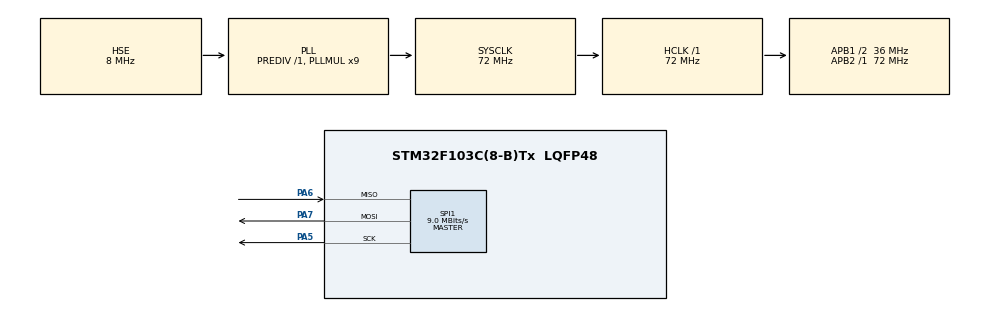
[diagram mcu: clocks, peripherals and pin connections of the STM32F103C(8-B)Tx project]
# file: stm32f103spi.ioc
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Dma.Request0=SPI1_RX
Dma.Request1=SPI1_TX
Dma.SPI1_RX.0.Direction=DMA_PERIPH_TO_MEMORY
Dma.SPI1_RX.0.Instance=DMA1_Channel2
Dma.SPI1_RX.0.MemDataAlignment=DMA_MDATAALIGN_BYTE
Dma.SPI1_RX.0.MemInc=DMA_MINC_ENABLE
Dma.SPI1_RX.0.Mode=DMA_NORMAL
Dma.SPI1_RX.0.PeriphDataAlignment=DMA_PDATAALIGN_BYTE
Dma.SPI1_RX.0.PeriphInc=DMA_PINC_DISABLE
Dma.SPI1_RX.0.Priority=DMA_PRIORITY_LOW
Dma.SPI1_TX.1.Direction=DMA_MEMORY_TO_PERIPH
Dma.SPI1_TX.1.Instance=DMA1_Channel3
Dma.SPI1_TX.1.MemDataAlignment=DMA_MDATAALIGN_BYTE
Dma.SPI1_TX.1.MemInc=DMA_MINC_ENABLE
Dma.SPI1_TX.1.Mode=DMA_NORMAL
Dma.SPI1_TX.1.PeriphDataAlignment=DMA_PDATAALIGN_BYTE
Dma.SPI1_TX.1.PeriphInc=DMA_PINC_DISABLE
Dma.SPI1_TX.1.Priority=DMA_PRIORITY_LOW
Mcu.Family=STM32F1
Mcu.Name=STM32F103C(8-B)Tx
Mcu.Package=LQFP48
NVIC.DMA1_Channel2_IRQn=true\:0\:0\:false\:false\:true\:false\:true
NVIC.DMA1_Channel3_IRQn=true\:0\:0\:false\:false\:true\:false\:true
NVIC.PriorityGroup=NVIC_PRIORITYGROUP_4
NVIC.SPI1_IRQn=true\:0\:0\:false\:false\:true\:true\:true
PA5.Mode=Full_Duplex_Master
PA5.Signal=SPI1_SCK
PA6.Mode=Full_Duplex_Master
PA6.Signal=SPI1_MISO
PA7.Mode=Full_Duplex_Master
PA7.Signal=SPI1_MOSI
PD0-OSC_IN.Mode=HSE-External-Oscillator
PD0-OSC_IN.Signal=RCC_OSC_IN
PD1-OSC_OUT.Mode=HSE-External-Oscillator
PD1-OSC_OUT.Signal=RCC_OSC_OUT
ProjectManager.HeapSize=0x200
ProjectManager.StackSize=0x400
ProjectManager.TargetToolchain=MDK-ARM V5
RCC.AHBFreq_Value=72000000
RCC.APB1CLKDivider=RCC_HCLK_DIV2
RCC.APB1Freq_Value=36000000
RCC.APB1TimFreq_Value=72000000
RCC.APB2Freq_Value=72000000
RCC.APB2TimFreq_Value=72000000
RCC.HCLKFreq_Value=72000000
RCC.PLLMUL=RCC_PLL_MUL9
RCC.PLLSourceVirtual=RCC_PLLSOURCE_HSE
RCC.SYSCLKFreq_VALUE=72000000
RCC.SYSCLKSource=RCC_SYSCLKSOURCE_PLLCLK
RCC.USBFreq_Value=72000000
SPI1.BaudRatePrescaler=SPI_BAUDRATEPRESCALER_8
SPI1.CalculateBaudRate=9.0 MBits/s
SPI1.Direction=SPI_DIRECTION_2LINES
SPI1.Mode=SPI_MODE_MASTER
SPI1.VirtualType=VM_MASTER
VP_SYS_VS_ND.Mode=No_Debug
board=custom

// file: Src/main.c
/* USER CODE BEGIN Header */
/**
  ******************************************************************************
  * @file           : main.c
  * @brief          : Main program body
  ******************************************************************************
  * @attention
  *
  * <h2><center>&copy; Copyright (c) 2021 STMicroelectronics.
  * All rights reserved.</center></h2>
  *
  * This software component is licensed by ST under BSD 3-Clause license,
  * the "License"; You may not use this file except in compliance with the
  * License. You may obtain a copy of the License at:
  *                        opensource.org/licenses/BSD-3-Clause
  *
  ******************************************************************************
  */
/* USER CODE END Header */

#include "main.h"

SPI_HandleTypeDef hspi1;
DMA_HandleTypeDef hdma_spi1_rx;
DMA_HandleTypeDef hdma_spi1_tx;

void SystemClock_Config(void);
static void MX_GPIO_Init(void);
static void MX_DMA_Init(void);
static void MX_SPI1_Init(void);

int main(void)
{

  /* MCU Configuration--------------------------------------------------------*/

  /* Reset of all peripherals, Initializes the Flash interface and the Systick. */
  HAL_Init();

  /* Configure the system clock */
  SystemClock_Config();

  /* Initialize all configured peripherals */
  MX_GPIO_Init();
  MX_DMA_Init();
  MX_SPI1_Init();

  /* Infinite loop */
  /* USER CODE BEGIN WHILE */
  while (1)
  {
		uint8_t pData[4] = {0x00, 0x00, 0x00,0x00};
		static uint8_t cmd[4] = {0x00,0x01,0x02,0x03};
		//HAL_SPI_TransmitReceive(&hspi1, cmd, pData, 4, 10000);
		HAL_SPI_TransmitReceive_DMA(&hspi1, cmd, pData, 4);
		cmd[3] += 1;
		HAL_Delay(5);
//		if (HAL_SPI_Receive(&hspi1, pData,4,280843555) == HAL_OK){
//				if(pData[0] == 0x01 && pData[3] == 0x03){
//						cmd[3] += 1;
//
//				}
//
//		}
    /* USER CODE END WHILE */

  }
}

void SystemClock_Config(void)
{
  RCC_OscInitTypeDef RCC_OscInitStruct = {0};
  RCC_ClkInitTypeDef RCC_ClkInitStruct = {0};

  /** Initializes the CPU, AHB and APB busses clocks
  */
  RCC_OscInitStruct.OscillatorType = RCC_OSCILLATORTYPE_HSE;
  RCC_OscInitStruct.HSEState = RCC_HSE_ON;
  RCC_OscInitStruct.HSEPredivValue = RCC_HSE_PREDIV_DIV1;
  RCC_OscInitStruct.HSIState = RCC_HSI_ON;
  RCC_OscInitStruct.PLL.PLLState = RCC_PLL_ON;
  RCC_OscInitStruct.PLL.PLLSource = RCC_PLLSOURCE_HSE;
  RCC_OscInitStruct.PLL.PLLMUL = RCC_PLL_MUL9;
  if (HAL_RCC_OscConfig(&RCC_OscInitStruct) != HAL_OK)
  {
    Error_Handler();
  }
  /** Initializes the CPU, AHB and APB busses clocks
  */
  RCC_ClkInitStruct.ClockType = RCC_CLOCKTYPE_HCLK|RCC_CLOCKTYPE_SYSCLK
                              |RCC_CLOCKTYPE_PCLK1|RCC_CLOCKTYPE_PCLK2;
  RCC_ClkInitStruct.SYSCLKSource = RCC_SYSCLKSOURCE_PLLCLK;
  RCC_ClkInitStruct.AHBCLKDivider = RCC_SYSCLK_DIV1;
  RCC_ClkInitStruct.APB1CLKDivider = RCC_HCLK_DIV2;
  RCC_ClkInitStruct.APB2CLKDivider = RCC_HCLK_DIV1;

  if (HAL_RCC_ClockConfig(&RCC_ClkInitStruct, FLASH_LATENCY_2) != HAL_OK)
  {
    Error_Handler();
  }
}

static void MX_SPI1_Init(void)
{

  /* SPI1 parameter configuration*/
  hspi1.Instance = SPI1;
  hspi1.Init.Mode = SPI_MODE_MASTER;
  hspi1.Init.Direction = SPI_DIRECTION_2LINES;
  hspi1.Init.DataSize = SPI_DATASIZE_8BIT;
  hspi1.Init.CLKPolarity = SPI_POLARITY_LOW;
  hspi1.Init.CLKPhase = SPI_PHASE_1EDGE;
  hspi1.Init.NSS = SPI_NSS_SOFT;
  hspi1.Init.BaudRatePrescaler = SPI_BAUDRATEPRESCALER_8;
  hspi1.Init.FirstBit = SPI_FIRSTBIT_MSB;
  hspi1.Init.TIMode = SPI_TIMODE_DISABLE;
  hspi1.Init.CRCCalculation = SPI_CRCCALCULATION_DISABLE;
  hspi1.Init.CRCPolynomial = 10;
  if (HAL_SPI_Init(&hspi1) != HAL_OK)
  {
    Error_Handler();
  }

}

static void MX_DMA_Init(void)
{

  /* DMA controller clock enable */
  __HAL_RCC_DMA1_CLK_ENABLE();

  /* DMA interrupt init */
  /* DMA1_Channel2_IRQn interrupt configuration */
  HAL_NVIC_SetPriority(DMA1_Channel2_IRQn, 0, 0);
  HAL_NVIC_EnableIRQ(DMA1_Channel2_IRQn);
  /* DMA1_Channel3_IRQn interrupt configuration */
  HAL_NVIC_SetPriority(DMA1_Channel3_IRQn, 0, 0);
  HAL_NVIC_EnableIRQ(DMA1_Channel3_IRQn);

}

static void MX_GPIO_Init(void)
{

  /* GPIO Ports Clock Enable */
  __HAL_RCC_GPIOD_CLK_ENABLE();
  __HAL_RCC_GPIOA_CLK_ENABLE();

}

void Error_Handler(void)
{
}

/************************ (C) COPYRIGHT STMicroelectronics *****END OF FILE****/
